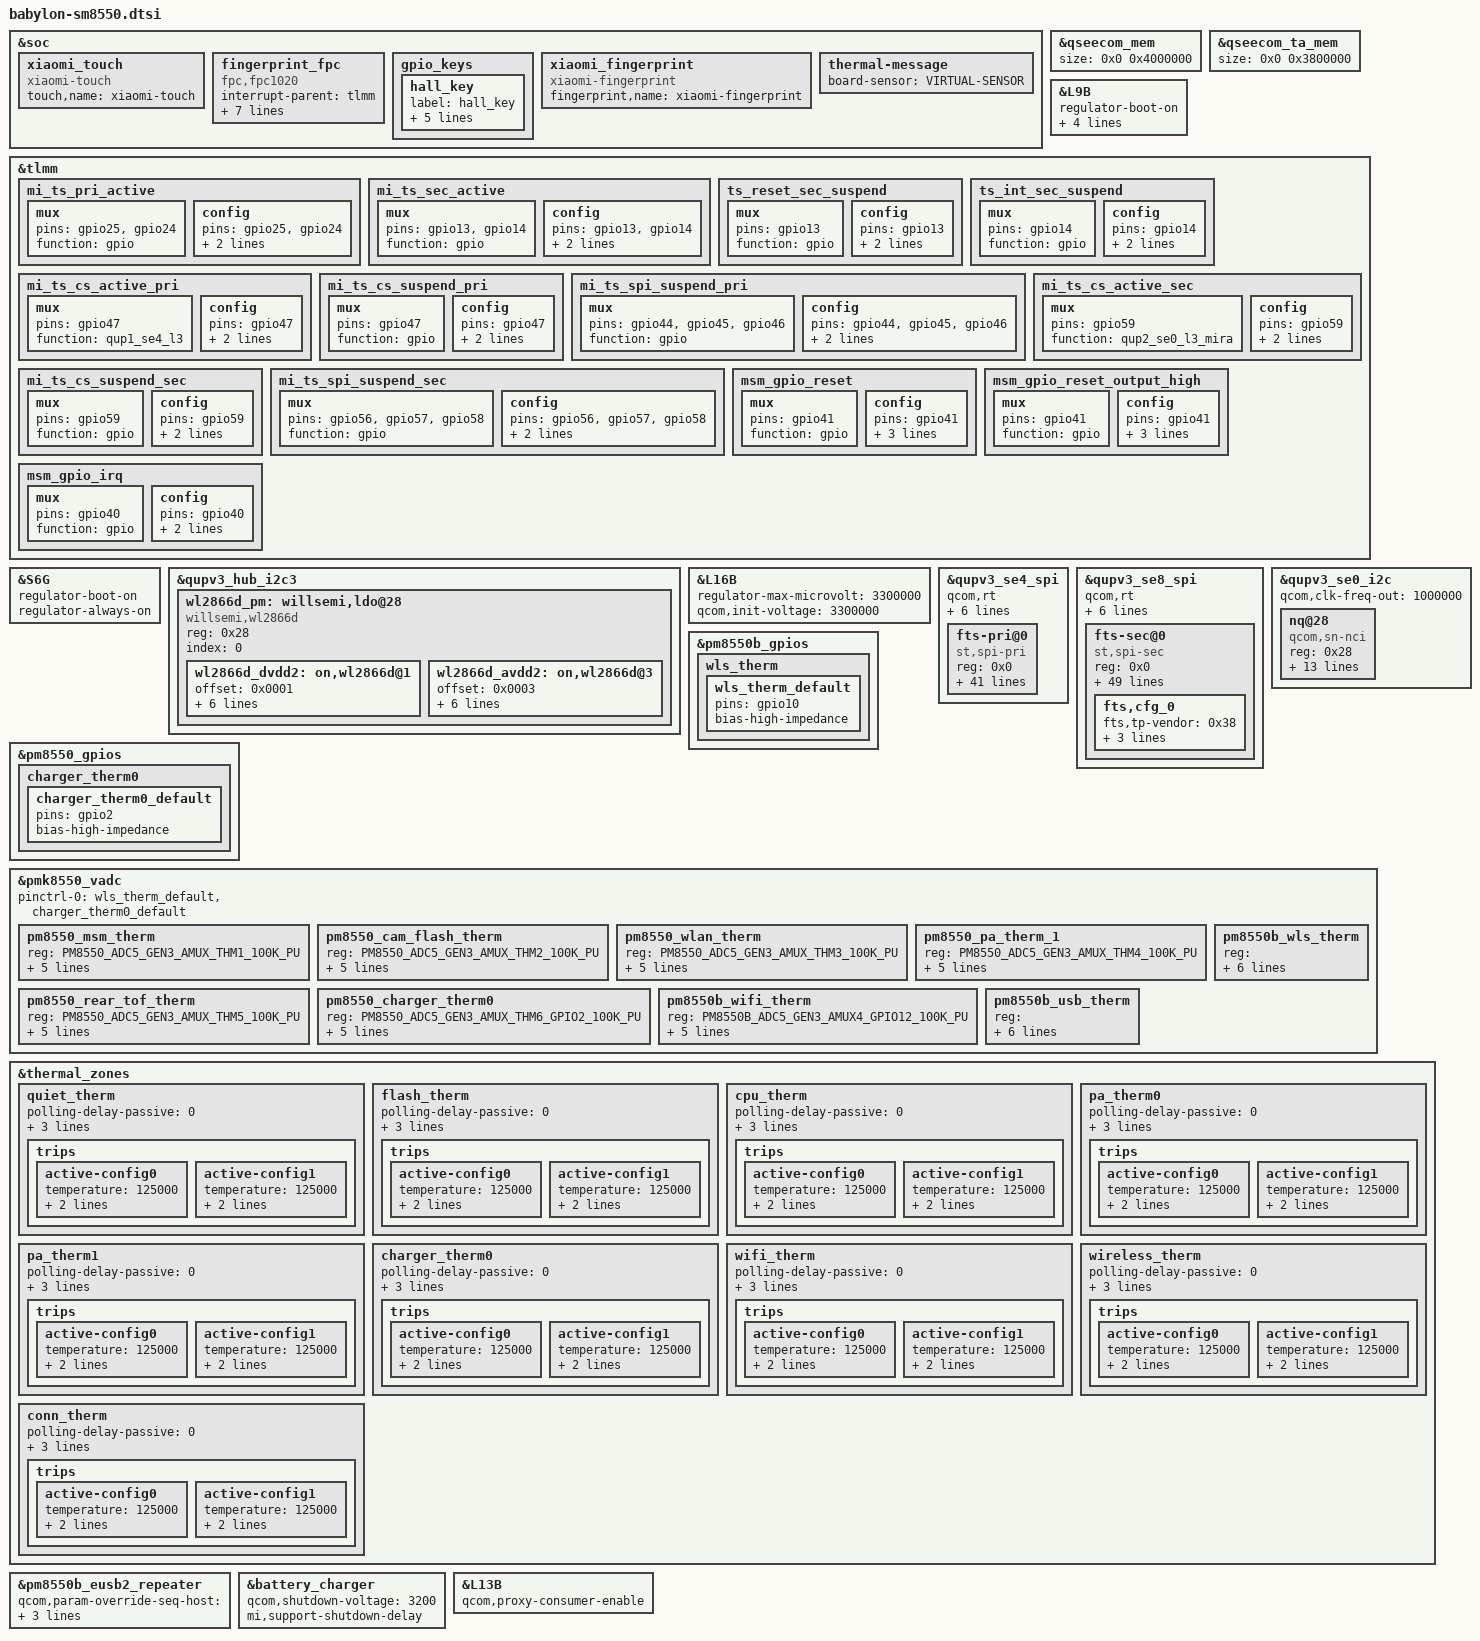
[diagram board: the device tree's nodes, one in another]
/*
  this file is for attribution only of zeus
  And public attribution of xiaomi platforms
*/

#define BABYLON_REGULATOR_OCP
#include "babylon-pinctrl.dtsi"
#include "xiaomi-sm8550-common.dtsi"
#include <dt-bindings/clock/qcom,rpmh.h>

&soc {
	xiaomi_touch {
		compatible = "xiaomi-touch";
		status = "ok";
		touch,name = "xiaomi-touch";
	};
	fingerprint_fpc {
		status = "ok";
		compatible = "fpc,fpc1020";
		interrupt-parent = <&tlmm>;
		interrupts = <40 0x0>;
		fpc,gpio_rst    = <&tlmm 41 0x0>;
		fpc,gpio_irq    = <&tlmm 40 0x0>;
		fp_vdd_vreg-supply = <&L9B>;
		pinctrl-names = "fpc1020_reset_reset",
				"fpc1020_reset_active",
				"fpc1020_irq_active";

		pinctrl-0 = <&msm_gpio_reset>;
		pinctrl-1 = <&msm_gpio_reset_output_high>;
		pinctrl-2 = <&msm_gpio_irq>;
	};
	gpio_keys {
		hall_key {
			label = "hall_key";
			gpios = <&tlmm 17 GPIO_ACTIVE_LOW>;
			linux,input-type = <5>;
			linux,code = <0>;
			gpio-key,wakeup;
			debounce-interval = <15>;
		};
	};
	xiaomi_fingerprint {
		compatible = "xiaomi-fingerprint";
		status = "ok";
		fingerprint,name = "xiaomi-fingerprint";
	};
};

&qseecom_mem {
		size = <0x0 0x4000000>;
};

&qseecom_ta_mem {
		size = <0x0 0x3800000>;
};

&L9B {
	regulator-boot-on;
	regulator-always-on;
	regulator-min-microvolt = <3300000>;
	regulator-max-microvolt = <3300000>;
	qcom,init-voltage = <3300000>;
};

&tlmm {
	/*
	wl2866d_enable_active: wl2866d_enable_active {
		mux {
				pins = "gpio125";
				function = "gpio";
		};

		config {
				pins = "gpio125";
				bias-disable;
				drive-strength = <2>;
				output-high;
		};
	};
	wl2866d_enable_suspend: wl2866d_enable_suspend {
		mux {
				pins = "gpio125";
				function = "gpio";
		};

		config {
				pins = "gpio125";
				bias-pull-down;
				drive-strength = <2>;
				output-low;
		};
	};
*/
	mi_ts_pri_active: mi_ts_pri_active {
		mux {
				pins = "gpio25", "gpio24";
				function = "gpio";
		};

		config {
				pins = "gpio25", "gpio24";
				drive-strength = <8>;
				bias-pull-up;
		};
	};
	mi_ts_sec_active: mi_ts_sec_active {
		mux {
				pins = "gpio13", "gpio14";
				function = "gpio";
		};

		config {
				pins = "gpio13", "gpio14";
				drive-strength = <8>;
				bias-pull-up;
		};
	};

	ts_reset_sec_suspend: ts_reset_sec_suspend {
		mux {
			pins = "gpio13";
			function = "gpio";
		};

		config {
			pins = "gpio13";
			drive-strength = <2>;
			bias-pull-down;
		};
	};

	ts_int_sec_suspend: ts_int_sec_suspend {
		mux {
			pins = "gpio14";
			function = "gpio";
		};

		config {
			pins = "gpio14";
			drive-strength = <2>;
			bias-pull-down;
		};
	};

	mi_ts_cs_active_pri: mi_ts_cs_active_pri {
		mux {
			pins = "gpio47";
			function = "qup1_se4_l3";
		};

		config {
			pins = "gpio47";
			drive-strength = <6>;
			bias-pull-up;
		};
	};

	mi_ts_cs_suspend_pri: mi_ts_cs_suspend_pri {
		mux {
			pins = "gpio47";
			function = "gpio";
		};

		config {
			pins = "gpio47";
			drive-strength = <16>;
			bias-pull-up;
		};
	};

	mi_ts_spi_suspend_pri: mi_ts_spi_suspend_pri {
		mux {
			pins = "gpio44", "gpio45", "gpio46";
			function = "gpio";
		};

		config {
			pins = "gpio44", "gpio45", "gpio46";
			drive-strength = <6>;
			bias-disable;
		};
	};

	mi_ts_cs_active_sec: mi_ts_cs_active_sec {
		mux {
			pins = "gpio59";
			function = "qup2_se0_l3_mira";
		};

		config {
			pins = "gpio59";
			drive-strength = <6>;
			bias-pull-up;
		};
	};

	mi_ts_cs_suspend_sec: mi_ts_cs_suspend_sec {
		mux {
			pins = "gpio59";
			function = "gpio";
		};

		config {
			pins = "gpio59";
			drive-strength = <16>;
			bias-pull-up;
		};
	};

	mi_ts_spi_suspend_sec: mi_ts_spi_suspend_sec {
		mux {
			pins = "gpio56", "gpio57", "gpio58";
			function = "gpio";
		};

		config {
			pins = "gpio56", "gpio57", "gpio58";
			drive-strength = <6>;
			bias-disable;
		};
	};

	/* FP_RESET_N */
	msm_gpio_reset: msm_gpio_reset {
		mux {
			pins = "gpio41";
			function = "gpio";
		};
		config {
			pins = "gpio41";
			drive-strength = <2>;
			bias-disable;
			output-low;
		};
	};

	/* FP_RESET_N, state device active*/
	msm_gpio_reset_output_high: msm_gpio_reset_output_high {
		mux {
			pins = "gpio41";
			function = "gpio";
		};
		config {
			pins = "gpio41";
			drive-strength = <2>;
			bias-disable;
			output-high;
		};
	};

	/* FP_INT_N */
	msm_gpio_irq: msm_gpio_irq {
		mux {
			pins = "gpio40";
			function = "gpio";
		};
		config {
			pins = "gpio40";
			drive-strength = <2>;
			bias-pull-down;
		};
	};
};

&S6G {
	regulator-boot-on;
	regulator-always-on;
};

&qupv3_hub_i2c3 {
	status = "ok";
	wl2866d_pm:willsemi,ldo@28 {
		compatible = "willsemi,wl2866d";
		reg = <0x28>;/*slave address*/
		index = <0>;
		/*
		pinctrl-names = "default";
	    pinctrl-0 = <&wl2866d_enable_active>;
		pinctrl-1 = <&wl2866d_enable_suspend>;
		*/
		/*
		wl2866d_dvdd1:on,wl2866d@0{
			offset = /bits/ 16 <0x0000>;
			regulator-name ="wl2866d-dvdd1";
			regulator-min-microvolt = <600000>;
			regulator-max-microvolt = <1800000>;
			min-dropout-voltage = <80000>;
			iout_ua = <500000>;
			init-voltage = <1800000>;
			regulator-boot-on;
		};
*/
		wl2866d_dvdd2:on,wl2866d@1{
			offset = /bits/ 16 <0x0001>;
			regulator-name ="wl2866d-dvdd2";
			regulator-min-microvolt = <600000>;
			regulator-max-microvolt = <1800000>;
			min-dropout-voltage = <80000>;
			iout_ua = <500000>;
			init-voltage = <1800000>;
		};
/*
		wl2866d_avdd1:on,wl2866d@2{
			offset = /bits/ 16 <0x0002>;
			regulator-name ="wl2866d-avdd1";
			regulator-min-microvolt = <1200000>;
			regulator-max-microvolt = <4300000>;
			min-dropout-voltage = <90000>;
			iout_ua = <300000>;
			init-voltage = <3000000>;
		};
*/
		wl2866d_avdd2:on,wl2866d@3{
			offset = /bits/ 16 <0x0003>;
			regulator-name ="wl2866d-avdd2";
			regulator-min-microvolt = <1200000>;
			regulator-max-microvolt = <4300000>;
			min-dropout-voltage = <90000>;
			iout_ua = <300000>;
			init-voltage = <3300000>;
		};
	};
};

&L16B {
	regulator-max-microvolt = <3300000>;
	qcom,init-voltage = <3300000>;
};

&qupv3_se4_spi {
	status = "ok";
	qcom,rt;
	pinctrl-0 = <&qupv3_se4_spi_mosi_active>, <&qupv3_se4_spi_miso_active>,
				<&qupv3_se4_spi_clk_active>, <&mi_ts_cs_active_pri>;
	pinctrl-1 = <&mi_ts_spi_suspend_pri &mi_ts_cs_suspend_pri>;
	fts-pri@0 {
		status = "ok";
		compatible = "st,spi-pri";
		reg = <0x0>;
		interrupt-parent = <&tlmm>;
		interrupts = <25 0x2008>;
		pinctrl-names = "pmx_ts_pri_active", "pmx_ts_pri_suspend";
		pinctrl-0 = <&mi_ts_pri_active>;
		pinctrl-1 = <&ts_int_suspend &ts_reset_suspend>;
		avdd-supply = <&L16B>;
		dvdd-supply = <&L12B>;
		fts,regulator_avdd = "avdd";
		fts,regulator_dvdd = "dvdd";
		fts,x-max = <19140>;
		fts,y-max = <21600>;
		fts,irq-gpio = <&tlmm 25 0x2008>;
		fts,reset-gpio = <&tlmm 24 0x00>;
		fts,support-super-resolution = <1>;
		fts,touch-follow-performance-def = <4>;
		fts,touch-tap-sensitivity-def = <4>;
		fts,touch-aim-sensitivity-def = <4>;
		fts,touch-tap-stability-def = <3>;
		fts,cornerfilter-area-step1 = <100>;
		fts,cornerfilter-area-step2 = <170>;
		fts,cornerfilter-area-step3 = <250>;
		fts,touch-deadzone-filter-ver = <2 0 0 0 0 0 0 0
										2 1 0 0 0 0 0 0
										2 2 0 0 0 0 0 0
										2 3 0 0 0 0 0 0>;
		fts,touch-deadzone-filter-hor = <2 0 0 0 0 0 0 0
										2 1 0 0 0 0 0 0
										2 2 0 0 0 0 0 0
										2 3 0 0 0 0 0 0>;
		fts,touch-edgezone-filter-ver = <1 0 0 0 0 0 0 0
										1 1 0 0 0 0 0 0
										1 2 0 0 30 2159 0 0
										1 3 1883 0 1913 2159 0 0>;
		fts,touch-edgezone-filter-hor = <1 0 0 0 1913 30 0 0
										1 1 0 2129 1913 2159 0 0
										1 2 0 0 30 2159 0 0
										1 3 0 0 0 0 0 0>;
		fts,touch-cornerzone-filter-ver = <0 0 0 0 0 0 0 0
										0 1 0 0 0 0 0 0
										0 2 0 1859 150 2159 0 0
										0 3 1763 1859 1913 2159 0 0>;
		fts,touch-cornerzone-filter-hor1 = <0 0 0 0 170 170 0 0
										0 1 0 0 0 0 0 0
										0 2 0 1989 170 2159 0 0
										0 3 0 0 0 0 0 0>;
		fts,touch-cornerzone-filter-hor2 = <0 0 0 0 0 0 0 0
										0 1 1743 0 1913 170 0 0
										0 2 0 0 0 0 0 0
										0 3 1743 1989 1913 2159 0 0>;
		fts,touch-follow-performance = <10 14 1
										8 14 1
										6 14 1
										4 14 1
										2 14 1>;
		fts,touch-tap-sensitivity = <55 48 42 36 30>;
		fts,touch-aim-sensitivity = <10 8 6 4 2>;
		fts,touch-tap-stability = <8 12 15 18 25>;
		fts,touch-expert-array = <4 14 1 36 4 15
								  2 14 1 55 4 15
								  4 14 1 55 2 15>;
	};
};

&qupv3_se8_spi {
	status = "ok";
	qcom,rt;
    pinctrl-0 = <&qupv3_se8_spi_miso_active>, <&qupv3_se8_spi_mosi_active>,
				<&qupv3_se8_spi_clk_active>, <&mi_ts_cs_active_sec>;
	pinctrl-1 = <&mi_ts_spi_suspend_sec &mi_ts_cs_suspend_sec>;
	fts-sec@0 {
		status = "ok";
		compatible = "st,spi-sec";
		reg = <0x0>;
		interrupt-parent = <&tlmm>;
		interrupts = <14 0x2008>;
		pinctrl-names = "pmx_ts_sec_active", "pmx_ts_sec_suspend";
		pinctrl-0 = <&mi_ts_sec_active>;
		pinctrl-1 = <&ts_int_sec_suspend &ts_reset_sec_suspend>;
		avdd-supply = <&wl2866d_avdd2>;
		vdd-supply = <&wl2866d_dvdd2>;
		/*panel = <&dsi_k8_42_02_0a_dsc_cmd>;*/
		fts,pwr-reg-name = "avdd";
		fts,bus-reg-name = "vdd";
		fts,irq-gpio = <&tlmm 14 0x2008>;
		fts,irq-gpio-name = "fts_irq";
		fts,reset-gpio-enable;
		fts,reset-gpio = <&tlmm 13 0x00>;
		fts,reset-gpio-name = "fts_rst";
		fts,irq-flags = <0x2008>;
		fts,x-max = <10800>;
		fts,y-max = <25200>;
		spi-max-frequency = <12000000>;
		fts,support-super-resolution = <1>;
		fts,default-fw-name = "st_fts_sec.ftb";
		fts,config-array-size = <1>;
		fts,touch-follow-performance-def = <4>;
		fts,touch-tap-sensitivity-def = <4>;
		fts,touch-aim-sensitivity-def = <4>;
		fts,touch-tap-stability-def = <3>;
		fts,cornerfilter-area-step1 = <100>;
		fts,cornerfilter-area-step2 = <170>;
		fts,cornerfilter-area-step3 = <250>;
		fts,touch-deadzone-filter-ver = <2 0 0 0 0 0 0 0
										2 1 0 0 0 0 0 0
										2 2 0 0 0 0 0 0
										2 3 0 0 0 0 0 0>;
		fts,touch-deadzone-filter-hor = <2 0 0 0 0 0 0 0
										2 1 0 0 0 0 0 0
										2 2 0 0 0 0 0 0
										2 3 0 0 0 0 0 0>;
		fts,touch-edgezone-filter-ver = <1 0 0 0 0 0 0 0
										1 1 0 0 0 0 0 0
										1 2 0 0 40 2519 0 0
										1 3 1039 0 1079 2519 0 0>;
		fts,touch-edgezone-filter-hor = <1 0 0 0 1079 40 0 0
										1 1 0 2479 1079 2519 0 0
										1 2 0 0 40 2519 0 0
										1 3 1039 0 1079 2519 0 0>;
		fts,touch-cornerzone-filter-ver = <0 0 0 0 0 0 0 0
										0 1 0 0 0 0 0 0
										0 2 0 2219 150 2519 0 0
										0 3 929 2219 1079 2519 0 0>;
		fts,touch-cornerzone-filter-hor1 = <0 0 0 0 170 170 0 0
										0 1 0 0 0 0 0 0
										0 2 0 2349 170 2519 0 0
										0 3 0 0 0 0 0 0>;
		fts,touch-cornerzone-filter-hor2 = <0 0 0 0 0 0 0 0
										0 1 909 0 1079 170 0 0
										0 2 0 0 0 0 0 0
										0 3 909 2349 1079 2519 0 0>;
		fts,touch-follow-performance = <10 15 1
										8 15 1
										6 15 1
										4 15 1
										2 15 1>;
		fts,touch-tap-sensitivity = <60 52 45 38 30>;
		fts,touch-aim-sensitivity = <10 8 6 4 2>;
		fts,touch-tap-stability = <8 12 15 18 25>;
		fts,touch-expert-array = <4 15 1 38 4 15
								  2 15 1 60 4 15
								  4 15 1 60 2 15>;
		fts,cfg_0 {
			fts,tp-vendor = <0x38>;
			fts,fw-name = "st_fts_sec.ftb";
			fts,limit-name = "stm_fts_production_limits_sec.csv";
		};
	};
};

&qupv3_se0_i2c {
	status = "ok";
	qcom,clk-freq-out = <1000000>;
	#address-cells = <1>;
	#size-cells = <0>;
	nq@28 {
		compatible = "qcom,sn-nci";
		reg = <0x28>;
		qcom,sn-irq = <&tlmm 55 0x00>;
		qcom,sn-ven = <&tlmm 30 0x00>;
		qcom,sn-firm = <&tlmm 12 0x00>;
		qcom,sn-clkreq = <&tlmm 31 0x00>;
		qcom,sn-szone = "enable";
		qcom,sn-vdd-1p8-supply = <&L15B>;
		qcom,sn-vdd-1p8-voltage = <1760000 1800000>;
		qcom,sn-vdd-1p8-current = <157000>;
		interrupt-parent = <&tlmm>;
		interrupts = <55 0>;
		interrupt-names = "nfc_irq";
		pinctrl-names = "nfc_active", "nfc_suspend";
		pinctrl-0 = <&nfc_int_active &nfc_enable_active>;
		pinctrl-1 = <&nfc_int_suspend &nfc_enable_suspend>;
		/*below clocks only need for Kailua V1 device */
		clocks = <&rpmhcc RPMH_LN_BB_CLK2>;
		clock-names = "nfc_ref_clk";
	};
};

&pm8550b_gpios {
	wls_therm {
		wls_therm_default: wls_therm_default {
		pins = "gpio10";
		bias-high-impedance;
	};
	};
};

&pm8550_gpios {
	charger_therm0 {
		charger_therm0_default: charger_therm0_default {
		pins = "gpio2";
		bias-high-impedance;
	};
	};
};

&pmk8550_vadc {
	pinctrl-names = "default";
	pinctrl-0 = <&wls_therm_default>, <&charger_therm0_default>;
	pm8550_msm_therm {
		reg = <PM8550_ADC5_GEN3_AMUX_THM1_100K_PU>;
		label = "pm8550_msm_therm";
		qcom,ratiometric;
		qcom,hw-settle-time = <200>;
		qcom,pre-scaling = <1 1>;
		qcom,adc-tm-type = <1>;
	};

	pm8550_cam_flash_therm {
		reg = <PM8550_ADC5_GEN3_AMUX_THM2_100K_PU>;
		label = "pm8550_cam_flash_therm";
		qcom,ratiometric;
		qcom,hw-settle-time = <200>;
		qcom,pre-scaling = <1 1>;
		qcom,adc-tm-type = <1>;
	};

	pm8550_wlan_therm {
		reg = <PM8550_ADC5_GEN3_AMUX_THM3_100K_PU>;
		label = "pm8550_wlan_therm";
		qcom,ratiometric;
		qcom,hw-settle-time = <200>;
		qcom,pre-scaling = <1 1>;
		qcom,adc-tm-type = <1>;
	};

	pm8550_pa_therm_1 {
		reg = <PM8550_ADC5_GEN3_AMUX_THM4_100K_PU>;
		label = "pm8550_pa_therm_1";
		qcom,ratiometric;
		qcom,hw-settle-time = <200>;
		qcom,pre-scaling = <1 1>;
		qcom,adc-tm-type = <1>;
	};

	pm8550_rear_tof_therm {
		reg = <PM8550_ADC5_GEN3_AMUX_THM5_100K_PU>;
		label = "pm8550_rear_tof_therm";
		qcom,ratiometric;
		qcom,hw-settle-time = <200>;
		qcom,pre-scaling = <1 1>;
		qcom,adc-tm-type = <1>;
	};

	pm8550_charger_therm0 {
		reg = <PM8550_ADC5_GEN3_AMUX_THM6_GPIO2_100K_PU>;
		label = "pm8550_charger_therm0";
		qcom,ratiometric;
		qcom,hw-settle-time = <200>;
		qcom,pre-scaling = <1 1>;
		qcom,adc-tm-type = <1>;
	};

	pm8550b_wls_therm {
		reg = <PM8550B_ADC5_GEN3_AMUX_THM6_GPIO10_100K_PU>;
		label = "pm8550b_wls_therm";
		qcom,ratiometric;
		qcom,hw-settle-time = <200>;
		qcom,pre-scaling = <1 1>;
		qcom,adc-tm-type = <1>;
	};

	pm8550b_wifi_therm {
		reg = <PM8550B_ADC5_GEN3_AMUX4_GPIO12_100K_PU>;
		label = "pm8550b_wifi_therm";
		qcom,ratiometric;
		qcom,hw-settle-time = <200>;
		qcom,pre-scaling = <1 1>;
		qcom,adc-tm-type = <1>;
	};

	pm8550b_usb_therm {
		reg = <PM8550B_ADC5_GEN3_AMUX_THM4_USB_THERM_100K_PU>;
		label = "pm8550b_usb_therm";
		qcom,ratiometric;
		qcom,hw-settle-time = <200>;
		qcom,pre-scaling = <1 1>;
		qcom,adc-tm-type = <1>;
	};
};

&thermal_zones {
	quiet_therm {
		polling-delay-passive = <0>;
		polling-delay = <0>;
		thermal-sensors = <&pmk8550_vadc PM8550_ADC5_GEN3_AMUX_THM1_100K_PU>;
		trips {
			active-config0 {
				temperature = <125000>;
				hysteresis = <1000>;
				type = "passive";
			};

			active-config1 {
				temperature = <125000>;
				hysteresis = <1000>;
				type = "passive";
			};
		};
	};

	flash_therm {
		polling-delay-passive = <0>;
		polling-delay = <0>;
		thermal-sensors = <&pmk8550_vadc PM8550_ADC5_GEN3_AMUX_THM2_100K_PU>;
		trips {
			active-config0 {
				temperature = <125000>;
				hysteresis = <1000>;
				type = "passive";
			};

			active-config1 {
				temperature = <125000>;
				hysteresis = <1000>;
				type = "passive";
			};
		};
	};

	cpu_therm {
		polling-delay-passive = <0>;
		polling-delay = <0>;
		thermal-sensors = <&pmk8550_vadc PM8550_ADC5_GEN3_AMUX_THM3_100K_PU>;
		trips {
			active-config0 {
				temperature = <125000>;
				hysteresis = <1000>;
				type = "passive";
			};

			active-config1 {
				temperature = <125000>;
				hysteresis = <1000>;
				type = "passive";
			};
		};
	};

	pa_therm0 {
		polling-delay-passive = <0>;
		polling-delay = <0>;
		thermal-sensors = <&pmk8550_vadc PM8550_ADC5_GEN3_AMUX_THM4_100K_PU>;
		trips {
			active-config0 {
				temperature = <125000>;
				hysteresis = <1000>;
				type = "passive";
			};

			active-config1 {
				temperature = <125000>;
				hysteresis = <1000>;
				type = "passive";
			};
		};
	};

	pa_therm1 {
		polling-delay-passive = <0>;
		polling-delay = <0>;
		thermal-sensors = <&pmk8550_vadc PM8550_ADC5_GEN3_AMUX_THM5_100K_PU>;
		trips {
			active-config0 {
				temperature = <125000>;
				hysteresis = <1000>;
				type = "passive";
			};

			active-config1 {
				temperature = <125000>;
				hysteresis = <1000>;
				type = "passive";
			};
		};
	};

	charger_therm0 {
		polling-delay-passive = <0>;
		polling-delay = <0>;
		thermal-sensors = <&pmk8550_vadc PM8550_ADC5_GEN3_AMUX_THM6_GPIO2_100K_PU>;
		trips {
			active-config0 {
				temperature = <125000>;
				hysteresis = <1000>;
				type = "passive";
			};

			active-config1 {
				temperature = <125000>;
				hysteresis = <1000>;
				type = "passive";
			};
		};
	};

	wifi_therm {
		polling-delay-passive = <0>;
		polling-delay = <0>;
		thermal-sensors = <&pmk8550_vadc PM8550B_ADC5_GEN3_AMUX4_GPIO12_100K_PU>;
		trips {
			active-config0 {
				temperature = <125000>;
				hysteresis = <1000>;
				type = "passive";
			};

			active-config1 {
				temperature = <125000>;
				hysteresis = <1000>;
				type = "passive";
			};
		};
	};

	wireless_therm {
		polling-delay-passive = <0>;
		polling-delay = <0>;
		thermal-sensors = <&pmk8550_vadc PM8550B_ADC5_GEN3_AMUX_THM6_GPIO10_100K_PU>;
		trips {
			active-config0 {
				temperature = <125000>;
				hysteresis = <1000>;
				type = "passive";
			};

			active-config1 {
				temperature = <125000>;
				hysteresis = <1000>;
				type = "passive";
			};
		};
	};

	conn_therm {
		polling-delay-passive = <0>;
		polling-delay = <0>;
		thermal-sensors = <&pmk8550_vadc PM8550B_ADC5_GEN3_AMUX_THM4_USB_THERM_100K_PU>;
		trips {
			active-config0 {
				temperature = <125000>;
				hysteresis = <1000>;
				type = "passive";
			};

			active-config1 {
				temperature = <125000>;
				hysteresis = <1000>;
				type = "passive";
			};
		};
	};
};

&soc {
	thermal-message {
		board-sensor = "VIRTUAL-SENSOR";
	};
};

&pm8550b_eusb2_repeater {
	qcom,param-override-seq-host =
		<0x00 0x50
		0x0c 0x51
		0x03 0x52
                0x06 0x53
		0x02 0x54
		0x03 0x55
		0x03 0x57>;
	qcom,param-override-seq =
		<0x00 0x50
		0x0c 0x51
		0x03 0x52
		0x06 0x53
		0x02 0x54
		0x03 0x55
		0x05 0x57>;
};
&battery_charger {
	qcom,shutdown-voltage = <3200>;
	mi,support-shutdown-delay;
};

&L13B {
    qcom,proxy-consumer-enable;
};
